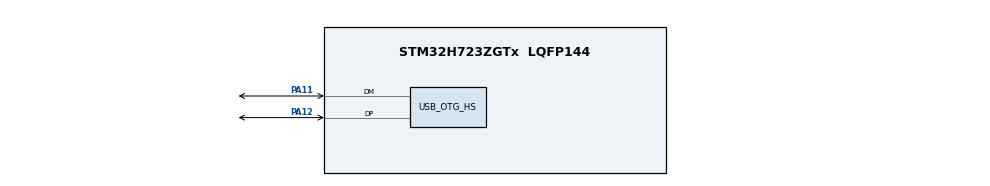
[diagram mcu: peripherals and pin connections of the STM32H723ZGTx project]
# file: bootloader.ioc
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CORTEX_M7.default_mode_Activation=1
Mcu.Family=STM32H7
Mcu.Name=STM32H723ZGTx
Mcu.Package=LQFP144
NVIC.OTG_HS_IRQn=true\:0\:0\:false\:false\:true\:false\:true\:true
NVIC.PriorityGroup=NVIC_PRIORITYGROUP_4
PA11.Mode=Device_Only_FS
PA11.Signal=USB_OTG_HS_DM
PA12.Mode=Device_Only_FS
PA12.Signal=USB_OTG_HS_DP
PA13(JTMS/SWDIO).Mode=Serial_Wire
PA13(JTMS/SWDIO).Signal=DEBUG_JTMS-SWDIO
PA14(JTCK/SWCLK).Mode=Serial_Wire
PA14(JTCK/SWCLK).Signal=DEBUG_JTCK-SWCLK
ProjectManager.HeapSize=0x200
ProjectManager.StackSize=0x400
ProjectManager.TargetToolchain=CMake
RCC.ADCFreq_Value=129000000
RCC.APB1Freq_Value=64000000
RCC.APB2Freq_Value=64000000
RCC.APB3Freq_Value=64000000
RCC.APB4Freq_Value=64000000
RCC.CortexFreq_Value=64000000
RCC.HCLKFreq_Value=64000000
RCC.SYSCLKFreq_VALUE=64000000
RCC.USBCLockSelection=RCC_USBCLKSOURCE_HSI48
RCC.USBFreq_Value=48000000
USB_DEVICE.CLASS_NAME_HS=CDC
USB_DEVICE.VirtualMode=Cdc
USB_DEVICE.VirtualModeHS=Cdc_HS
USB_OTG_HS.VirtualMode-Device_Only_FS=Device_Only_FS
VP_MEMORYMAP_VS_MEMORYMAP.Mode=CurAppReg
VP_USB_DEVICE_VS_USB_DEVICE_CDC_HS.Mode=CDC_HS
board=custom

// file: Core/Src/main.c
/* USER CODE BEGIN Header */
/**
  ******************************************************************************
  * @file           : main.c
  * @brief          : Main program body
  ******************************************************************************
  * @attention
  *
  * Copyright (c) 2026 STMicroelectronics.
  * All rights reserved.
  *
  * This software is licensed under terms that can be found in the LICENSE file
  * in the root directory of this software component.
  * If no LICENSE file comes with this software, it is provided AS-IS.
  *
  ******************************************************************************
  */
/* USER CODE END Header */
#include "main.h"
#include "usb_device.h"

/* USER CODE BEGIN Includes */
#include "boot_manager.h"
#include "boot_protocol.h"
#include "boot_request.h"

/* USER CODE END Includes */

void SystemClock_Config(void);
static void MPU_Config(void);
static void MX_GPIO_Init(void);

int main(void)
{

  /* MPU Configuration--------------------------------------------------------*/
  MPU_Config();

  /* MCU Configuration--------------------------------------------------------*/

  /* Reset of all peripherals, Initializes the Flash interface and the Systick. */
  HAL_Init();

  /* Configure the system clock */
  SystemClock_Config();

  /* Initialize all configured peripherals */
  MX_GPIO_Init();
  /* USER CODE BEGIN 2 */

  /* A requested update or no bootable image owns the USB recovery path. */
  if (boot_request_consume_update() || !boot_manager_run())
  {
    MX_USB_DEVICE_Init();
    boot_protocol_init();
  }

  /* USER CODE END 2 */

  /* Infinite loop */
  while (1)
  {

    /* USER CODE BEGIN 3 */
    boot_protocol_poll();
  }
  /* USER CODE END 3 */
}

void SystemClock_Config(void)
{
  RCC_OscInitTypeDef RCC_OscInitStruct = {0};
  RCC_ClkInitTypeDef RCC_ClkInitStruct = {0};

  /** Supply configuration update enable
  */
  HAL_PWREx_ConfigSupply(PWR_LDO_SUPPLY);

  /** Configure the main internal regulator output voltage
  */
  __HAL_PWR_VOLTAGESCALING_CONFIG(PWR_REGULATOR_VOLTAGE_SCALE3);

  while(!__HAL_PWR_GET_FLAG(PWR_FLAG_VOSRDY)) {}

  /** Initializes the RCC Oscillators according to the specified parameters
  * in the RCC_OscInitTypeDef structure.
  */
  RCC_OscInitStruct.OscillatorType = RCC_OSCILLATORTYPE_HSI48|RCC_OSCILLATORTYPE_HSI;
  RCC_OscInitStruct.HSIState = RCC_HSI_DIV1;
  RCC_OscInitStruct.HSICalibrationValue = 64;
  RCC_OscInitStruct.HSI48State = RCC_HSI48_ON;
  RCC_OscInitStruct.PLL.PLLState = RCC_PLL_NONE;
  if (HAL_RCC_OscConfig(&RCC_OscInitStruct) != HAL_OK)
  {
    Error_Handler();
  }

  /** Initializes the CPU, AHB and APB buses clocks
  */
  RCC_ClkInitStruct.ClockType = RCC_CLOCKTYPE_HCLK|RCC_CLOCKTYPE_SYSCLK
                              |RCC_CLOCKTYPE_PCLK1|RCC_CLOCKTYPE_PCLK2
                              |RCC_CLOCKTYPE_D3PCLK1|RCC_CLOCKTYPE_D1PCLK1;
  RCC_ClkInitStruct.SYSCLKSource = RCC_SYSCLKSOURCE_HSI;
  RCC_ClkInitStruct.SYSCLKDivider = RCC_SYSCLK_DIV1;
  RCC_ClkInitStruct.AHBCLKDivider = RCC_HCLK_DIV1;
  RCC_ClkInitStruct.APB3CLKDivider = RCC_APB3_DIV1;
  RCC_ClkInitStruct.APB1CLKDivider = RCC_APB1_DIV1;
  RCC_ClkInitStruct.APB2CLKDivider = RCC_APB2_DIV1;
  RCC_ClkInitStruct.APB4CLKDivider = RCC_APB4_DIV1;

  if (HAL_RCC_ClockConfig(&RCC_ClkInitStruct, FLASH_LATENCY_1) != HAL_OK)
  {
    Error_Handler();
  }
}

static void MX_GPIO_Init(void)
{

  /* GPIO Ports Clock Enable */
  __HAL_RCC_GPIOA_CLK_ENABLE();

}

 /* MPU Configuration */

void MPU_Config(void)
{
  MPU_Region_InitTypeDef MPU_InitStruct = {0};

  /* Disables the MPU */
  HAL_MPU_Disable();

  /** Initializes and configures the Region and the memory to be protected
  */
  MPU_InitStruct.Enable = MPU_REGION_ENABLE;
  MPU_InitStruct.Number = MPU_REGION_NUMBER0;
  MPU_InitStruct.BaseAddress = 0x0;
  MPU_InitStruct.Size = MPU_REGION_SIZE_4GB;
  MPU_InitStruct.SubRegionDisable = 0x87;
  MPU_InitStruct.TypeExtField = MPU_TEX_LEVEL0;
  MPU_InitStruct.AccessPermission = MPU_REGION_NO_ACCESS;
  MPU_InitStruct.DisableExec = MPU_INSTRUCTION_ACCESS_DISABLE;
  MPU_InitStruct.IsShareable = MPU_ACCESS_SHAREABLE;
  MPU_InitStruct.IsCacheable = MPU_ACCESS_NOT_CACHEABLE;
  MPU_InitStruct.IsBufferable = MPU_ACCESS_NOT_BUFFERABLE;

  HAL_MPU_ConfigRegion(&MPU_InitStruct);
  /* Enables the MPU */
  HAL_MPU_Enable(MPU_PRIVILEGED_DEFAULT);

}

void Error_Handler(void)
{
  __disable_irq();
  while (1)
  {
  }
}
